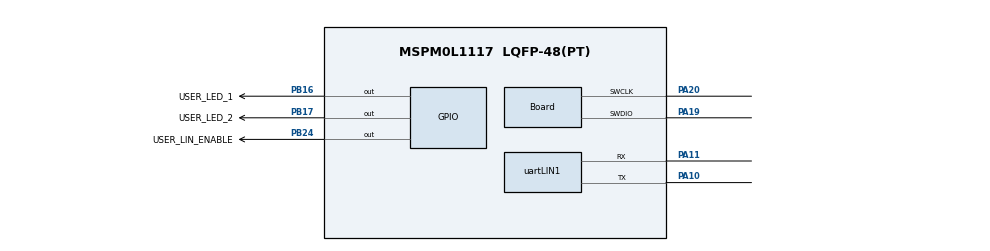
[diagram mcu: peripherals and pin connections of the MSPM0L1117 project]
//@cliArgs --device "MSPM0L111X" --package "LQFP-48(PT)" --part "Default"
//@v2CliArgs --device "MSPM0L1117" --package "LQFP-48(PT)"
// @cliArgs --board /ti/boards/LP_MSPM0L1117 --rtos nortos

/**
 * Import the modules used in this configuration.
 */
const Board    = scripting.addModule("/ti/driverlib/Board");
const GPIO     = scripting.addModule("/ti/driverlib/GPIO", {}, false);
const GPIO1    = GPIO.addInstance();
const GPIO2    = GPIO.addInstance();
const GPIO3    = GPIO.addInstance();
const GPIO4    = GPIO.addInstance();
const SYSCTL   = scripting.addModule("/ti/driverlib/SYSCTL");
const uartLIN  = scripting.addModule("/ti/driverlib/uartLIN", {}, false);
const uartLIN1 = uartLIN.addInstance();

/**
 * Write custom configuration values to the imported modules.
 */
Board.peripheral.$assign          = "DEBUGSS";
Board.peripheral.swclkPin.$assign = "PA20";
Board.peripheral.swdioPin.$assign = "PA19";

GPIO1.$name                         = "GPIO_LEDS";
GPIO1.port                          = "PORTB";
GPIO1.portSegment                   = "Upper";
GPIO1.associatedPins.create(2);
GPIO1.associatedPins[0].$name       = "USER_LED_1";
GPIO1.associatedPins[0].assignedPin = "16";
GPIO1.associatedPins[0].pin.$assign = "PB16";
GPIO1.associatedPins[1].$name       = "USER_LED_2";
GPIO1.associatedPins[1].assignedPin = "17";
GPIO1.associatedPins[1].pin.$assign = "PB17";

GPIO2.$name                         = "GPIO_LIN_ENABLE";
GPIO2.port                          = "PORTB";
GPIO2.portSegment                   = "Upper";
GPIO2.associatedPins[0].$name       = "USER_LIN_ENABLE";
GPIO2.associatedPins[0].assignedPin = "24";
GPIO2.associatedPins[0].pin.$assign = "PB24";

GPIO3.$name                              = "GPIO_SWITCHES1";
GPIO3.port                               = "PORTA";
GPIO3.portSegment                        = "Lower";
GPIO3.associatedPins[0].direction        = "INPUT";
GPIO3.associatedPins[0].interruptEn      = true;
GPIO3.associatedPins[0].$name            = "USER_SWITCH_1";
GPIO3.associatedPins[0].assignedPin      = "5";
GPIO3.associatedPins[0].polarity         = "FALL";
GPIO3.associatedPins[0].internalResistor = "PULL_UP";

GPIO4.$name                         = "GPIO_SWITCHES2";
GPIO4.port                          = "PORTA";
GPIO4.portSegment                   = "Upper";
GPIO4.associatedPins[0].$name       = "USER_SWITCH_2";
GPIO4.associatedPins[0].direction   = "INPUT";
GPIO4.associatedPins[0].assignedPin = "18";
GPIO4.associatedPins[0].interruptEn = true;
GPIO4.associatedPins[0].polarity    = "RISE";

SYSCTL.clockTreeEn           = true;

uartLIN1.$name                    = "LIN_0";
uartLIN1.targetBaudRate           = 19200;
uartLIN1.tbitVal                  = 9.5;
uartLIN1.enableDMARX              = false;
uartLIN1.enableDMATX              = false;
uartLIN1.enabledInterrupts        = ["RX"];
uartLIN1.peripheral.$assign       = "UART0";
uartLIN1.peripheral.rxPin.$assign = "PA11";
uartLIN1.peripheral.txPin.$assign = "PA10";

const ProjectConfig              = scripting.addModule("/ti/project_config/ProjectConfig", {}, false);
ProjectConfig.migrationCondition = true;
